# SAMPLE register map
Registers are access not given, no defined reset value unless marked. A register's access mark holds for its fields unless they carry their own. Offsets are from the block's base; lines under a group give offsets from that group; [hi:lo] are bit positions; {n}, {i} and the like mark numbered series; 'fields as' and 'values as' point back to an identical list; <NAME> marks a mode.

## Memory map
? RCC

## RCC
Base ?
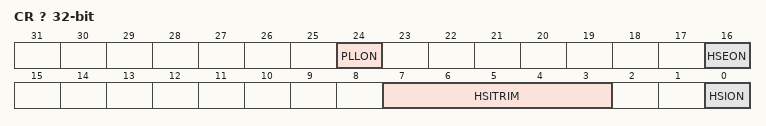
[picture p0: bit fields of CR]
? CR
  [24] PLLON, [16] HSEON, [7:3] HSITRIM, [0] HSION
